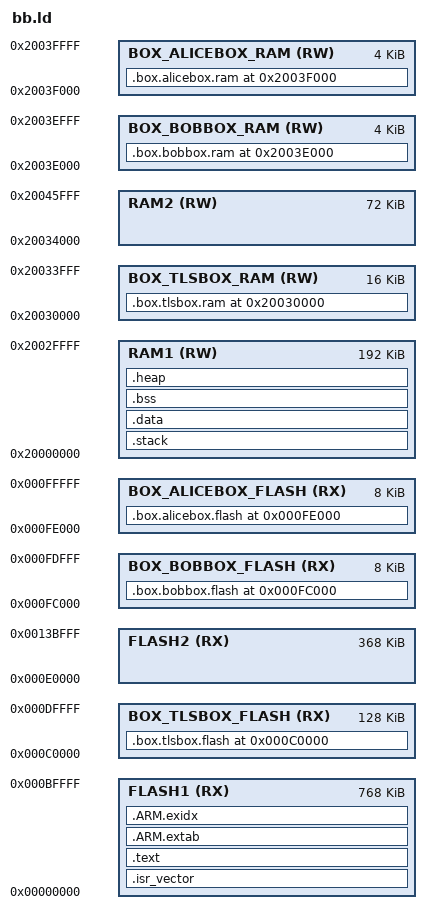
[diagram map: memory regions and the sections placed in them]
/***** AUTOGENERATED *****/

/* box calls */
__box_alicebox_rawinit = 0x1e000000 + 1*4 + 1*2 + 1;
__box_bobbox_rawinit = 0x1e000000 + 2*4 + 1*2 + 1;
__box_tlsbox_rawinit = 0x1e000000 + 3*4 + 1*2 + 1;
__box_alicebox_raw_alicebox_getpubkey = 0x1e000000 + 5*4 + 1*2 + 1;
__box_alicebox_raw_alicebox_init = 0x1e000000 + 9*4 + 1*2 + 1;
__box_alicebox_raw_alicebox_main = 0x1e000000 + 13*4 + 1*2 + 1;
__box_alicebox_raw_alicebox_recv = 0x1e000000 + 17*4 + 1*2 + 1;
__box_alicebox_raw_alicebox_tempbuffer = 0x1e000000 + 21*4 + 0*2 + 1;
__box_bobbox_raw_bobbox_getpubkey = 0x1e000000 + 6*4 + 1*2 + 1;
__box_bobbox_raw_bobbox_init = 0x1e000000 + 10*4 + 1*2 + 1;
__box_bobbox_raw_bobbox_main = 0x1e000000 + 14*4 + 1*2 + 1;
__box_bobbox_raw_bobbox_recv = 0x1e000000 + 18*4 + 1*2 + 1;
__box_bobbox_raw_bobbox_tempbuffer = 0x1e000000 + 22*4 + 0*2 + 1;
__box_tlsbox_raw_tlsbox_drbg_seed = 0x1e000000 + 7*4 + 1*2 + 1;
__box_tlsbox_raw_tlsbox_rsa_freekey = 0x1e000000 + 11*4 + 1*2 + 1;
__box_tlsbox_raw_tlsbox_rsa_fromprivkey = 0x1e000000 + 15*4 + 1*2 + 1;
__box_tlsbox_raw_tlsbox_rsa_frompubkey = 0x1e000000 + 19*4 + 1*2 + 1;
__box_tlsbox_raw_tlsbox_rsa_genkey = 0x1e000000 + 23*4 + 1*2 + 1;
__box_tlsbox_raw_tlsbox_rsa_getprivkey = 0x1e000000 + 27*4 + 1*2 + 1;
__box_tlsbox_raw_tlsbox_rsa_getpubkey = 0x1e000000 + 31*4 + 1*2 + 1;
__box_tlsbox_raw_tlsbox_rsa_pkcs1_decrypt = 0x1e000000 + 35*4 + 1*2 + 1;
__box_tlsbox_raw_tlsbox_rsa_pkcs1_encrypt = 0x1e000000 + 39*4 + 1*2 + 1;
__box_tlsbox_raw_tlsbox_tempbuffer = 0x1e000000 + 43*4 + 0*2 + 1;

ENTRY(__box_reset_handler)

/* overridable constants */
__stack_min      = DEFINED(__stack_min) ? __stack_min : 0x00001000;
__heap_min       = DEFINED(__heap_min) ? __heap_min : 0x00001000;

MEMORY {
    FLASH1           (RX ) : ORIGIN = 0x00000000, LENGTH = 0x000c0000
    BOX_TLSBOX_FLASH (RX ) : ORIGIN = 0x000c0000, LENGTH = 0x00020000
    FLASH2           (RX ) : ORIGIN = 0x000e0000, LENGTH = 0x0005c000
    BOX_BOBBOX_FLASH (RX ) : ORIGIN = 0x000fc000, LENGTH = 0x00002000
    BOX_ALICEBOX_FLASH (RX ) : ORIGIN = 0x000fe000, LENGTH = 0x00002000
    RAM1             (RW ) : ORIGIN = 0x20000000, LENGTH = 0x00030000
    BOX_TLSBOX_RAM   (RW ) : ORIGIN = 0x20030000, LENGTH = 0x00004000
    RAM2             (RW ) : ORIGIN = 0x20034000, LENGTH = 0x00012000
    BOX_BOBBOX_RAM   (RW ) : ORIGIN = 0x2003e000, LENGTH = 0x00001000
    BOX_ALICEBOX_RAM (RW ) : ORIGIN = 0x2003f000, LENGTH = 0x00001000
}

SECTIONS {
    /* FLASH1 sections */
    . = ORIGIN(FLASH1);
    . = ALIGN(4);
    __isr_vector_start = .;
    .isr_vector . : {
        KEEP(*(.isr_vector))
        . = __isr_vector_start + 0x400;
    } > FLASH1
    . = ALIGN(4);
    __isr_vector_end = .;

    . = ALIGN(4);
    __text_start = .;
    .text . : {
        *(.text*)
        *(.rodata*)
        *(.glue_7*)
        *(.glue_7t*)
        *(.eh_frame*)

        KEEP(*(SORT_NONE(.init)))
        KEEP(*(SORT_NONE(.init*)))
        KEEP(*(SORT_NONE(.fini)))
        KEEP(*(SORT_NONE(.fini*)))

        . = ALIGN(4);
        PROVIDE_HIDDEN(__preinit_array_start = .);
        KEEP(*(SORT(.preinit_array)))
        PROVIDE_HIDDEN(__preinit_array_end = .);

        . = ALIGN(4);
        PROVIDE_HIDDEN(__init_array_start = .);
        KEEP(*(SORT(.init_array.*)))
        PROVIDE_HIDDEN(__init_array_end = .);

        . = ALIGN(4);
        PROVIDE_HIDDEN(__fini_array_start = .);
        KEEP(*(SORT(.fini_array.*)))
        PROVIDE_HIDDEN(__fini_array_end = .);

        KEEP(*crtbegin.o(.ctors))
        KEEP(*crtbegin?.o(.ctors))
        KEEP(*(EXCLUDE_FILE(*crtend?.o *crtend.o) .ctors))
        KEEP(*(SORT(.ctors.*)))

        KEEP(*crtbegin.o(.dtors))
        KEEP(*crtbegin?.o(.dtors))
        KEEP(*(EXCLUDE_FILE(*crtend?.o *crtend.o) .dtors))
        KEEP(*(SORT(.dtors.*)))
    } > FLASH1
    . = ALIGN(4);
    __text_end = .;

    __extab_start = .;
    .ARM.extab : {
        *(.ARM.extab* .gnu.linkonce.armextab.*)
    } > FLASH1
    __extab_end = .;

    __exidx_start = .;
    .ARM.exidx : {
        *(.ARM.exidx* .gnu.linkonce.armexidx.*)
    } > FLASH1
    __exidx_end = .;

    . = ALIGN(4);
    __data_init_start = .;

    /* BOX_TLSBOX_FLASH sections */
    . = ORIGIN(BOX_TLSBOX_FLASH);
    __box_tlsbox_flash_start = .;
    .box.tlsbox.flash . : {
        KEEP(*(.box.tlsbox.flash*))
    } > BOX_TLSBOX_FLASH
    . = ORIGIN(BOX_TLSBOX_FLASH) + LENGTH(BOX_TLSBOX_FLASH);
    __box_tlsbox_flash_end = .;

    __box_tlsbox_jumptable = __box_tlsbox_flash_start;

    /* BOX_BOBBOX_FLASH sections */
    . = ORIGIN(BOX_BOBBOX_FLASH);
    __box_bobbox_flash_start = .;
    .box.bobbox.flash . : {
        KEEP(*(.box.bobbox.flash*))
    } > BOX_BOBBOX_FLASH
    . = ORIGIN(BOX_BOBBOX_FLASH) + LENGTH(BOX_BOBBOX_FLASH);
    __box_bobbox_flash_end = .;

    __box_bobbox_jumptable = __box_bobbox_flash_start;

    /* BOX_ALICEBOX_FLASH sections */
    . = ORIGIN(BOX_ALICEBOX_FLASH);
    __box_alicebox_flash_start = .;
    .box.alicebox.flash . : {
        KEEP(*(.box.alicebox.flash*))
    } > BOX_ALICEBOX_FLASH
    . = ORIGIN(BOX_ALICEBOX_FLASH) + LENGTH(BOX_ALICEBOX_FLASH);
    __box_alicebox_flash_end = .;

    __box_alicebox_jumptable = __box_alicebox_flash_start;

    /* RAM1 sections */
    . = ORIGIN(RAM1);
    . = ALIGN(4);
    __stack_start = .;
    .stack . (NOLOAD) : {
        . = .;
    } > RAM1
    . += __stack_min;
    . = ALIGN(4);
    __stack_end = .;

    . = ALIGN(4);
    __data_start = .;
    .data . : AT(__data_init_start) {
        *(.data*)
    } > RAM1
    . = ALIGN(4);
    __data_end = .;

    __data_init_end = LOADADDR(.data) + SIZEOF(.data);
    ASSERT(__data_init_end <= ORIGIN(FLASH1) + LENGTH(FLASH1),
        "Not enough memory in FLASH1 for data init")

    . = ALIGN(4);
    __bss_start = .;
    __bss_start__ = .;
    .bss . (NOLOAD) : {
        *(.bss*)
        *(COMMON)
    } > RAM1
    . = ALIGN(4);
    __bss_end = .;
    __bss_end__ = .;

    . = ALIGN(4);
    __heap_start = .;
    __end__ = .;
    PROVIDE(end = .);
    .heap . (NOLOAD) : {
        . = .;
    } > RAM1
    . = ORIGIN(RAM1) + LENGTH(RAM1);
    . = ALIGN(4);
    __heap_end = .;
    __heap_limit = .;

    ASSERT(__heap_end - __heap_start > __heap_min,
        "Not enough memory in RAM1 for heap")

    /* BOX_TLSBOX_RAM sections */
    . = ORIGIN(BOX_TLSBOX_RAM);
    __box_tlsbox_ram_start = .;
    .box.tlsbox.ram . (NOLOAD): {
        KEEP(*(.box.tlsbox.ram*))
    } > BOX_TLSBOX_RAM
    . = ORIGIN(BOX_TLSBOX_RAM) + LENGTH(BOX_TLSBOX_RAM);
    __box_tlsbox_ram_end = .;

    /* BOX_BOBBOX_RAM sections */
    . = ORIGIN(BOX_BOBBOX_RAM);
    __box_bobbox_ram_start = .;
    .box.bobbox.ram . (NOLOAD): {
        KEEP(*(.box.bobbox.ram*))
    } > BOX_BOBBOX_RAM
    . = ORIGIN(BOX_BOBBOX_RAM) + LENGTH(BOX_BOBBOX_RAM);
    __box_bobbox_ram_end = .;

    /* BOX_ALICEBOX_RAM sections */
    . = ORIGIN(BOX_ALICEBOX_RAM);
    __box_alicebox_ram_start = .;
    .box.alicebox.ram . (NOLOAD): {
        KEEP(*(.box.alicebox.ram*))
    } > BOX_ALICEBOX_RAM
    . = ORIGIN(BOX_ALICEBOX_RAM) + LENGTH(BOX_ALICEBOX_RAM);
    __box_alicebox_ram_end = .;
}

